VERSION ""

NS_ :

BS_:

BU_:

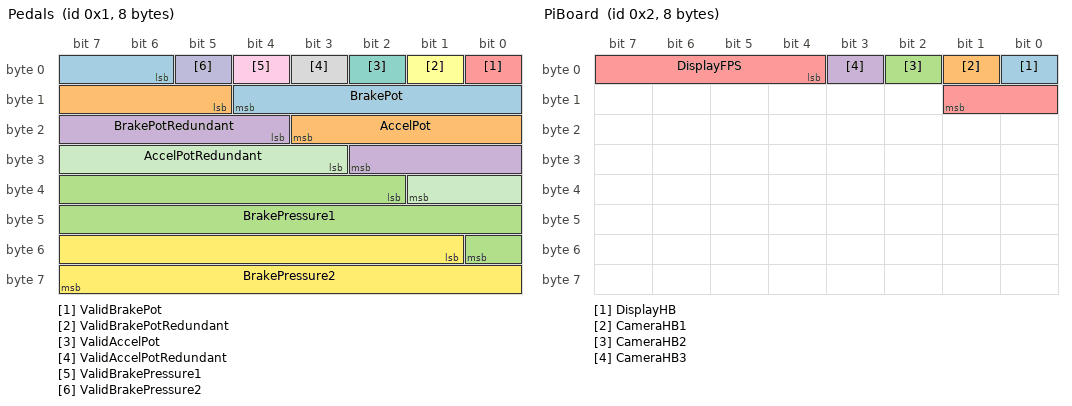
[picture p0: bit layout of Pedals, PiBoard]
BO_ 1 Pedals: 8 Vector__XXX
	SG_ BrakePot : 6|7@1+ (1,0) [0|100] "Percent" Vector__XXX
	SG_ AccelPot : 13|7@1+ (1,0) [0|100] "Percent" Vector__XXX
	SG_ BrakePressure1 : 34|15@1+ (0.1,0) [0|30000] "PSI" Vector__XXX
	SG_ BrakePotRedundant : 20|7@1+ (1,0) [0|100] "Percent" Vector__XXX
	SG_ ValidBrakePot : 0|1@1+ (1,0) [0|1] "Binary" Vector__XXX
	SG_ ValidBrakePotRedundant : 1|1@1+ (1,0) [0|1] "Binary" Vector__XXX
	SG_ ValidAccelPot : 2|1@1+ (1,0) [0|1] "Binary" Vector__XXX
	SG_ ValidAccelPotRedundant : 3|1@1+ (1,0) [0|1] "Binary" Vector__XXX
	SG_ ValidBrakePressure1 : 4|1@1+ (1,0) [0|1] "Binary" Vector__XXX
	SG_ ValidBrakePressure2 : 5|1@1+ (1,0) [0|1] "Binary" Vector__XXX
	SG_ AccelPotRedundant : 27|7@1+ (1,0) [0|100] "Percent" Vector__XXX
	SG_ BrakePressure2 : 49|15@1+ (0.1,0) [0|30000] "PSI" Vector__XXX

BO_ 2 PiBoard: 8 Vector__XXX
	SG_ DisplayHB : 0|1@1+ (1,0) [0|1] "Binary" Vector__XXX
	SG_ CameraHB1 : 1|1@1+ (1,0) [0|1] "Binary" Vector__XXX
	SG_ CameraHB2 : 2|1@1+ (1,0) [0|1] "Binary" Vector__XXX
	SG_ CameraHB3 : 3|1@1+ (1,0) [0|1] "Binary" Vector__XXX
	SG_ DisplayFPS : 4|6@1+ (1,0) [0|63] "FPS" Vector__XXX

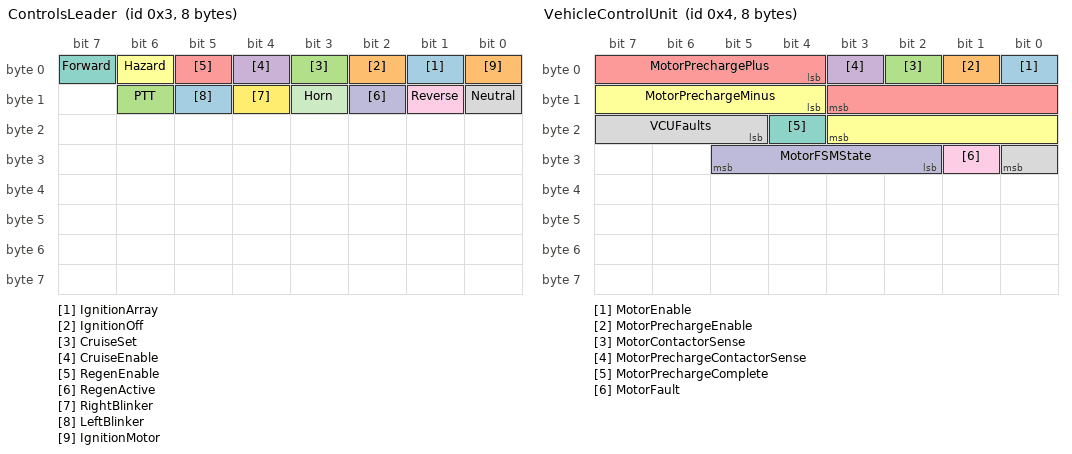
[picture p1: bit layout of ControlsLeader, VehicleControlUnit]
BO_ 3 ControlsLeader: 8 Vector__XXX
	SG_ IgnitionArray : 1|1@1+ (1,0) [0|1] "Binary" Vector__XXX
	SG_ IgnitionOff : 2|1@1+ (1,0) [0|1] "Binary" Vector__XXX
	SG_ CruiseSet : 3|1@1+ (1,0) [0|1] "Binary" Vector__XXX
	SG_ CruiseEnable : 4|1@1+ (1,0) [0|1] "Binary" Vector__XXX
	SG_ RegenEnable : 5|1@1+ (1,0) [0|1] "Binary" Vector__XXX
	SG_ Hazard : 6|1@1+ (1,0) [0|1] "Binary" Vector__XXX
	SG_ Forward : 7|1@1+ (1,0) [0|1] "Binary" Vector__XXX
	SG_ Neutral : 8|1@1+ (1,0) [0|1] "Binary" Vector__XXX
	SG_ Reverse : 9|1@1+ (1,0) [0|1] "Binary" Vector__XXX
	SG_ RegenActive : 10|1@1+ (1,0) [0|1] "Binary" Vector__XXX
	SG_ Horn : 11|1@1+ (1,0) [0|1] "Binary" Vector__XXX
	SG_ RightBlinker : 12|1@1+ (1,0) [0|1] "Binary" Vector__XXX
	SG_ LeftBlinker : 13|1@1+ (1,0) [0|1] "Binary" Vector__XXX
	SG_ IgnitionMotor : 0|1@1+ (1,0) [0|1] "Binary" Vector__XXX
	SG_ PTT : 14|1@1+ (1,0) [0|1] "Binary" Vector__XXX

BO_ 688 LWS_Standard: 8 Vector__XXX
	SG_  : 0|0@1+ (0,0) [0|0] "" Vector__XXX

BO_ 1984 LWS_Config: 8 Vector__XXX
	SG_  : 0|0@1+ (0,0) [0|0] "" Vector__XXX

BO_ 4 VehicleControlUnit: 8 Vector__XXX
	SG_ MotorEnable : 0|1@1+ (1,0) [0|1] "Binary" Vector__XXX
	SG_ MotorPrechargeEnable : 1|1@1+ (1,0) [0|1] "Binary" Vector__XXX
	SG_ MotorContactorSense : 2|1@1+ (1,0) [0|1] "Binary" Vector__XXX
	SG_ MotorPrechargeContactorSense : 3|1@1+ (1,0) [0|1] "Binary" Vector__XXX
	SG_ MotorPrechargePlus : 4|8@1+ (1,0) [0|135] "Volts" Vector__XXX
	SG_ MotorPrechargeMinus : 12|8@1+ (1,0) [0|135] "Volts" Vector__XXX
	SG_ MotorPrechargeComplete : 20|1@1+ (1,0) [0|1] "Binary" Vector__XXX
	SG_ VCUFaults : 21|4@1+ (1,0) [0|15] "Binary" Vector__XXX
	SG_ MotorFault : 25|1@1+ (1,0) [0|1] "Binary" Vector__XXX
	SG_ MotorFSMState : 26|4@1+ (1,0) [0|1] "Binary" Vector__XXX

CM_ BO_ 1 "Pedals board";
CM_ BO_ 2 "Pi board";
CM_ BO_ 3 "Controls Leader";
CM_ SG_ 3 PTT "Push to Talk";
CM_ BO_ 688 "LWS_Standard (Controls Leader Passthrough)";
CM_ BO_ 1984 "LWS Standard (Controls Leader Passthrough)";
CM_ BO_ 4 "VCU";
BA_DEF_ SG_  "SPN" INT 0 524287;
BA_DEF_ BO_  "VFrameFormat" ENUM  "StandardCAN","ExtendedCAN","reserved","J1939PG";
BA_DEF_  "DatabaseVersion" STRING ;
BA_DEF_  "BusType" STRING ;
BA_DEF_  "ProtocolType" STRING ;
BA_DEF_  "DatabaseCompiler" STRING ;
BA_DEF_DEF_  "SPN" 0;
BA_DEF_DEF_  "VFrameFormat" "J1939PG";
BA_DEF_DEF_  "DatabaseVersion" "DEMO PLUS";
BA_DEF_DEF_  "BusType" "";
BA_DEF_DEF_  "ProtocolType" "";
BA_DEF_DEF_  "DatabaseCompiler" "";
BA_ "ProtocolType" "J1939";
BA_ "BusType" "CAN";
BA_ "DatabaseCompiler" "CSS ELECTRONICS (WWW.CSSELECTRONICS.COM)";
BA_ "DatabaseVersion" "1.0.0";
BA_ "SPN" SG_ 1 EngineSpeed 190;
